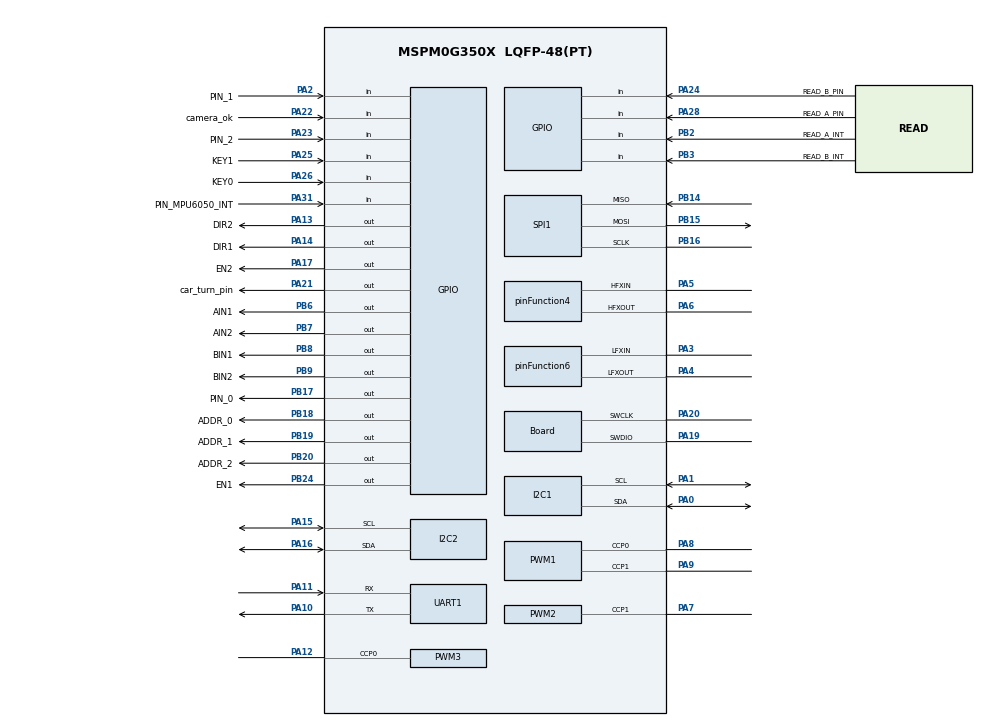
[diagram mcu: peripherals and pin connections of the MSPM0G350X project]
/**
 * @cliArgs --device "MSPM0G350X" --part "Default" --package "LQFP-48(PT)" --product "mspm0_sdk@2.05.01.00"
 * @versions {"tool":"1.24.1+4189"}
 */

/**
 * Import the modules used in this configuration.
 */
const ADC12   = scripting.addModule("/ti/driverlib/ADC12", {}, false);
const ADC121  = ADC12.addInstance();
const Board   = scripting.addModule("/ti/driverlib/Board");
const GPIO    = scripting.addModule("/ti/driverlib/GPIO", {}, false);
const GPIO1   = GPIO.addInstance();
const GPIO2   = GPIO.addInstance();
const GPIO3   = GPIO.addInstance();
const GPIO4   = GPIO.addInstance();
const GPIO5   = GPIO.addInstance();
const GPIO6   = GPIO.addInstance();
const GPIO7   = GPIO.addInstance();
const GPIO8   = GPIO.addInstance();
const GPIO9   = GPIO.addInstance();
const GPIO10  = GPIO.addInstance();
const I2C     = scripting.addModule("/ti/driverlib/I2C", {}, false);
const I2C1    = I2C.addInstance();
const I2C2    = I2C.addInstance();
const PWM     = scripting.addModule("/ti/driverlib/PWM", {}, false);
const PWM1    = PWM.addInstance();
const PWM2    = PWM.addInstance();
const PWM3    = PWM.addInstance();
const SPI     = scripting.addModule("/ti/driverlib/SPI", {}, false);
const SPI1    = SPI.addInstance();
const SYSCTL  = scripting.addModule("/ti/driverlib/SYSCTL");
const SYSTICK = scripting.addModule("/ti/driverlib/SYSTICK");
const TIMER   = scripting.addModule("/ti/driverlib/TIMER", {}, false);
const TIMER1  = TIMER.addInstance();
const TIMER2  = TIMER.addInstance();
const TIMER3  = TIMER.addInstance();
const UART    = scripting.addModule("/ti/driverlib/UART", {}, false);
const UART1   = UART.addInstance();

/**
 * Write custom configuration values to the imported modules.
 */
const divider2       = system.clockTree["HFCLK4MFPCLKDIV"];
divider2.divideValue = 10;

const divider9       = system.clockTree["UDIV"];
divider9.divideValue = 2;

const mux4       = system.clockTree["EXHFMUX"];
mux4.inputSelect = "EXHFMUX_XTAL";

const mux5       = system.clockTree["EXLFMUX"];
mux5.inputSelect = "EXLFMUX_XTAL";

const mux8       = system.clockTree["HSCLKMUX"];
mux8.inputSelect = "HSCLKMUX_SYSPLL2X";

const mux9       = system.clockTree["LFXTMUX"];
mux9.inputSelect = "LFXTMUX_TRUE";

const mux10       = system.clockTree["MFPCLKMUX"];
mux10.inputSelect = "MFPCLKMUX_HFCLK";

const mux12       = system.clockTree["SYSPLLMUX"];
mux12.inputSelect = "zSYSPLLMUX_HFCLK";

const pinFunction4                        = system.clockTree["HFXT"];
pinFunction4.enable                       = true;
pinFunction4.inputFreq                    = 40;
pinFunction4.HFXTStartup                  = 20;
pinFunction4.peripheral.$assign           = "SYSCTL";
pinFunction4.peripheral.hfxInPin.$assign  = "PA5";
pinFunction4.peripheral.hfxOutPin.$assign = "PA6";

const pinFunction6                        = system.clockTree["LFXT"];
pinFunction6.enable                       = true;
pinFunction6.inputFreq                    = 32.768;
pinFunction6.peripheral.$assign           = "SYSCTL";
pinFunction6.peripheral.lfxInPin.$assign  = "PA3";
pinFunction6.peripheral.lfxOutPin.$assign = "PA4";

ADC121.$name                             = "ADC_12_0_GRY";
ADC121.sampClkDiv                        = "DL_ADC12_CLOCK_DIVIDE_8";
ADC121.sampClkSrc                        = "DL_ADC12_CLOCK_ULPCLK";
ADC121.powerDownMode                     = "DL_ADC12_POWER_DOWN_MODE_MANUAL";
ADC121.peripheral.$assign                = "ADC0";
ADC121.peripheral.adcPin0.$assign        = "PA27";
ADC121.adcPin0Config.hideOutputInversion = scripting.forceWrite(false);
ADC121.adcPin0Config.$name               = "ti_driverlib_gpio_GPIOPinGeneric23";

Board.genPeriphPinFile            = true;
Board.peripheral.$assign          = "DEBUGSS";
Board.peripheral.swclkPin.$assign = "PA20";
Board.peripheral.swdioPin.$assign = "PA19";
Board.genFileMod.$name            = "ti_driverlib_BoardPins0";

GPIO1.$name                               = "ENCODER_READ_GRP";
GPIO1.associatedPins.create(4);
GPIO1.associatedPins[0].direction         = "INPUT";
GPIO1.associatedPins[0].$name             = "READ_A_INT";
GPIO1.associatedPins[0].interruptEn       = true;
GPIO1.associatedPins[0].polarity          = "FALL";
GPIO1.associatedPins[0].interruptPriority = "1";
GPIO1.associatedPins[0].pin.$assign       = "PB2";
GPIO1.associatedPins[1].$name             = "READ_B_INT";
GPIO1.associatedPins[1].direction         = "INPUT";
GPIO1.associatedPins[1].interruptEn       = true;
GPIO1.associatedPins[1].polarity          = "FALL";
GPIO1.associatedPins[1].interruptPriority = "1";
GPIO1.associatedPins[1].pin.$assign       = "PB3";
GPIO1.associatedPins[2].assignedPort      = "PORTA";
GPIO1.associatedPins[2].assignedPin       = "28";
GPIO1.associatedPins[2].$name             = "READ_A_PIN";
GPIO1.associatedPins[2].direction         = "INPUT";
GPIO1.associatedPins[2].interruptEn       = true;
GPIO1.associatedPins[2].polarity          = "FALL";
GPIO1.associatedPins[2].interruptPriority = "1";
GPIO1.associatedPins[2].pin.$assign       = "PA28";
GPIO1.associatedPins[3].$name             = "READ_B_PIN";
GPIO1.associatedPins[3].direction         = "INPUT";
GPIO1.associatedPins[3].interruptEn       = true;
GPIO1.associatedPins[3].polarity          = "FALL";
GPIO1.associatedPins[3].interruptPriority = "1";
GPIO1.associatedPins[3].pin.$assign       = "PA24";

GPIO2.$name                         = "TB6612_CONTROL_GRP";
GPIO2.associatedPins.create(4);
GPIO2.associatedPins[0].$name       = "AIN1";
GPIO2.associatedPins[0].pin.$assign = "PB6";
GPIO2.associatedPins[1].$name       = "AIN2";
GPIO2.associatedPins[1].pin.$assign = "PB7";
GPIO2.associatedPins[2].$name       = "BIN1";
GPIO2.associatedPins[2].pin.$assign = "PB8";
GPIO2.associatedPins[3].$name       = "BIN2";
GPIO2.associatedPins[3].pin.$assign = "PB9";

GPIO3.$name                         = "GRY_READ_GRP";
GPIO3.associatedPins.create(3);
GPIO3.associatedPins[0].$name       = "ADDR_0";
GPIO3.associatedPins[0].pin.$assign = "PB18";
GPIO3.associatedPins[1].$name       = "ADDR_1";
GPIO3.associatedPins[1].pin.$assign = "PB19";
GPIO3.associatedPins[2].$name       = "ADDR_2";
GPIO3.associatedPins[2].pin.$assign = "PB20";

GPIO4.$name                               = "GPIO_MPU6050";
GPIO4.associatedPins[0].direction         = "INPUT";
GPIO4.associatedPins[0].$name             = "PIN_MPU6050_INT";
GPIO4.associatedPins[0].interruptEn       = true;
GPIO4.associatedPins[0].polarity          = "FALL";
GPIO4.associatedPins[0].interruptPriority = "1";
GPIO4.associatedPins[0].pin.$assign       = "PA31";

GPIO5.$name                         = "KEYS";
GPIO5.associatedPins.create(2);
GPIO5.associatedPins[0].$name       = "KEY0";
GPIO5.associatedPins[0].direction   = "INPUT";
GPIO5.associatedPins[0].pin.$assign = "PA26";
GPIO5.associatedPins[1].$name       = "KEY1";
GPIO5.associatedPins[1].direction   = "INPUT";
GPIO5.associatedPins[1].pin.$assign = "PA25";

GPIO6.$name                         = "W25Q32_CS";
GPIO6.associatedPins[0].$name       = "PIN_0";
GPIO6.associatedPins[0].pin.$assign = "PB17";

GPIO7.$name                              = "EC11_READ";
GPIO7.associatedPins.create(2);
GPIO7.associatedPins[0].$name            = "PIN_1";
GPIO7.associatedPins[0].direction        = "INPUT";
GPIO7.associatedPins[0].ioStructure      = "SD";
GPIO7.associatedPins[0].internalResistor = "PULL_UP";
GPIO7.associatedPins[0].pin.$assign      = "PA2";
GPIO7.associatedPins[1].$name            = "PIN_2";
GPIO7.associatedPins[1].internalResistor = "PULL_UP";
GPIO7.associatedPins[1].direction        = "INPUT";
GPIO7.associatedPins[1].polarity         = "FALL";
GPIO7.associatedPins[1].interruptEn      = true;
GPIO7.associatedPins[1].ioStructure      = "SD";
GPIO7.associatedPins[1].pin.$assign      = "PA23";

GPIO8.$name                         = "STEP_MOTOR";
GPIO8.associatedPins.create(4);
GPIO8.associatedPins[0].$name       = "EN1";
GPIO8.associatedPins[0].pin.$assign = "PB24";
GPIO8.associatedPins[1].$name       = "EN2";
GPIO8.associatedPins[1].pin.$assign = "PA17";
GPIO8.associatedPins[2].$name       = "DIR1";
GPIO8.associatedPins[2].pin.$assign = "PA14";
GPIO8.associatedPins[3].$name       = "DIR2";
GPIO8.associatedPins[3].pin.$assign = "PA13";

GPIO9.$name                         = "car";
GPIO9.associatedPins[0].$name       = "car_turn_pin";
GPIO9.associatedPins[0].pin.$assign = "PA21";

GPIO10.$name                               = "camera";
GPIO10.associatedPins[0].$name             = "camera_ok";
GPIO10.associatedPins[0].direction         = "INPUT";
GPIO10.associatedPins[0].internalResistor  = "PULL_DOWN";
GPIO10.associatedPins[0].interruptEn       = true;
GPIO10.associatedPins[0].polarity          = "RISE";
GPIO10.associatedPins[0].interruptPriority = "1";
GPIO10.associatedPins[0].pin.$assign       = "PA22";

I2C1.basicEnableController             = true;
I2C1.basicControllerStandardBusSpeed   = "Fast";
I2C1.$name                             = "I2C_MPU6050";
I2C1.peripheral.$assign                = "I2C0";
I2C1.peripheral.sdaPin.$assign         = "PA0";
I2C1.peripheral.sclPin.$assign         = "PA1";
I2C1.sdaPinConfig.hideOutputInversion  = scripting.forceWrite(false);
I2C1.sdaPinConfig.onlyInternalResistor = scripting.forceWrite(false);
I2C1.sdaPinConfig.passedPeripheralType = scripting.forceWrite("Digital");
I2C1.sdaPinConfig.$name                = "ti_driverlib_gpio_GPIOPinGeneric13";
I2C1.sclPinConfig.hideOutputInversion  = scripting.forceWrite(false);
I2C1.sclPinConfig.onlyInternalResistor = scripting.forceWrite(false);
I2C1.sclPinConfig.passedPeripheralType = scripting.forceWrite("Digital");
I2C1.sclPinConfig.$name                = "ti_driverlib_gpio_GPIOPinGeneric14";

I2C2.$name                             = "I2C_1_OLED";
I2C2.basicEnableController             = true;
I2C2.basicControllerStandardBusSpeed   = "Fast";
I2C2.enableDMAEvent2                   = false;
I2C2.peripheral.$assign                = "I2C1";
I2C2.peripheral.sdaPin.$assign         = "PA16";
I2C2.peripheral.sclPin.$assign         = "PA15";
I2C2.sdaPinConfig.hideOutputInversion  = scripting.forceWrite(false);
I2C2.sdaPinConfig.onlyInternalResistor = scripting.forceWrite(false);
I2C2.sdaPinConfig.passedPeripheralType = scripting.forceWrite("Digital");
I2C2.sdaPinConfig.$name                = "ti_driverlib_gpio_GPIOPinGeneric11";
I2C2.sclPinConfig.hideOutputInversion  = scripting.forceWrite(false);
I2C2.sclPinConfig.onlyInternalResistor = scripting.forceWrite(false);
I2C2.sclPinConfig.passedPeripheralType = scripting.forceWrite("Digital");
I2C2.sclPinConfig.$name                = "ti_driverlib_gpio_GPIOPinGeneric12";

PWM1.$name                      = "PWM_0";
PWM1.clockDivider               = 4;
PWM1.pwmMode                    = "EDGE_ALIGN_UP";
PWM1.clockPrescale              = 10;
PWM1.peripheral.$assign         = "TIMA0";
PWM1.peripheral.ccp0Pin.$assign = "PA8";
PWM1.peripheral.ccp1Pin.$assign = "PA9";
PWM1.PWM_CHANNEL_0.$name        = "ti_driverlib_pwm_PWMTimerCC0";
PWM1.PWM_CHANNEL_1.$name        = "ti_driverlib_pwm_PWMTimerCC1";
PWM1.ccp0PinConfig.$name        = "ti_driverlib_gpio_GPIOPinGeneric18";
PWM1.ccp1PinConfig.$name        = "ti_driverlib_gpio_GPIOPinGeneric17";

PWM2.ccIndex                            = [1];
PWM2.$name                              = "PWM_C";
PWM2.clockDivider                       = 8;
PWM2.pwmMode                            = "CENTER_ALIGN";
PWM2.clockPrescale                      = 100;
PWM2.interrupts                         = ["CC1_UP_EVENT"];
PWM2.interruptPriority                  = "0";
PWM2.ccp1PinConfig.$name                = "ti_driverlib_gpio_GPIOPinGeneric8";
PWM2.ccp1PinConfig.direction            = scripting.forceWrite("OUTPUT");
PWM2.ccp1PinConfig.hideOutputInversion  = scripting.forceWrite(false);
PWM2.ccp1PinConfig.onlyInternalResistor = scripting.forceWrite(false);
PWM2.ccp1PinConfig.passedPeripheralType = scripting.forceWrite("Digital");
PWM2.peripheral.ccp1Pin.$assign         = "PA7";
PWM2.PWM_CHANNEL_1.$name                = "ti_driverlib_pwm_PWMTimerCC2";

PWM3.ccIndex                            = [0];
PWM3.$name                              = "PWM_D";
PWM3.clockDivider                       = 4;
PWM3.pwmMode                            = "CENTER_ALIGN";
PWM3.clockPrescale                      = 100;
PWM3.interrupts                         = ["CC0_UP_EVENT"];
PWM3.interruptPriority                  = "0";
PWM3.PWM_CHANNEL_0.$name                = "ti_driverlib_pwm_PWMTimerCC3";
PWM3.ccp0PinConfig.$name                = "ti_driverlib_gpio_GPIOPinGeneric9";
PWM3.ccp0PinConfig.direction            = scripting.forceWrite("OUTPUT");
PWM3.ccp0PinConfig.hideOutputInversion  = scripting.forceWrite(false);
PWM3.ccp0PinConfig.onlyInternalResistor = scripting.forceWrite(false);
PWM3.ccp0PinConfig.passedPeripheralType = scripting.forceWrite("Digital");
PWM3.peripheral.ccp0Pin.$assign         = "PA12";

SPI1.$name                      = "SPI_0";
SPI1.frameFormat                = "MOTO3";
SPI1.sclkPinConfig.$name        = "ti_driverlib_gpio_GPIOPinGeneric10";
SPI1.mosiPinConfig.$name        = "ti_driverlib_gpio_GPIOPinGeneric21";
SPI1.misoPinConfig.$name        = "ti_driverlib_gpio_GPIOPinGeneric22";
SPI1.peripheral.$assign         = "SPI1";
SPI1.peripheral.sclkPin.$assign = "PB16";
SPI1.peripheral.mosiPin.$assign = "PB15";
SPI1.peripheral.misoPin.$assign = "PB14";

SYSCTL.forceDefaultClkConfig = true;
SYSCTL.clockTreeEn           = true;
SYSCTL.MFPCLKSource          = "HFCLK";
scripting.suppress("For best practices when the CPUCLK is running at 32MHz and above, clear the flash status bit using DL_FlashCTL_executeClearStatus\\(\\) before executing any flash operation\\. Otherwise there may be false positives\\.", SYSCTL);

SYSTICK.periodEnable      = true;
SYSTICK.interruptEnable   = true;
SYSTICK.systickEnable     = true;
SYSTICK.interruptPriority = "0";
SYSTICK.period            = 16777216;

TIMER1.$name             = "TIMER_0";
TIMER1.timerMode         = "PERIODIC";
TIMER1.timerClkPrescale  = 200;
TIMER1.interrupts        = ["ZERO"];
TIMER1.timerPeriod       = "15ms";
TIMER1.interruptPriority = "2";

TIMER2.$name             = "TIMER_1";
TIMER2.timerMode         = "PERIODIC";
TIMER2.timerPeriod       = "10ms";
TIMER2.timerClkPrescale  = 200;
TIMER2.interrupts        = ["ZERO"];
TIMER2.interruptPriority = "3";

TIMER3.$name             = "TIMER_2";
TIMER3.timerClkDiv       = 8;
TIMER3.timerClkPrescale  = 100;
TIMER3.timerPeriod       = "5ms";
TIMER3.interrupts        = ["ZERO"];
TIMER3.timerMode         = "PERIODIC";
TIMER3.interruptPriority = "3";

UART1.$name                    = "UART_0";
UART1.targetBaudRate           = 115200;
UART1.enabledInterrupts        = ["RX"];
UART1.interruptPriority        = "1";
UART1.peripheral.$assign       = "UART0";
UART1.peripheral.rxPin.$assign = "PA11";
UART1.peripheral.txPin.$assign = "PA10";
UART1.txPinConfig.$name        = "ti_driverlib_gpio_GPIOPinGeneric6";
UART1.rxPinConfig.$name        = "ti_driverlib_gpio_GPIOPinGeneric7";

const ProjectConfig              = scripting.addModule("/ti/project_config/ProjectConfig", {}, false);
ProjectConfig.migrationCondition = true;

/**
 * Pinmux solution for unlocked pins/peripherals. This ensures that minor changes to the automatic solver in a future
 * version of the tool will not impact the pinmux you originally saw.  These lines can be completely deleted in order to
 * re-solve from scratch.
 */
PWM2.peripheral.$suggestSolution   = "TIMG7";
PWM3.peripheral.$suggestSolution   = "TIMG0";
TIMER1.peripheral.$suggestSolution = "TIMG8";
TIMER2.peripheral.$suggestSolution = "TIMG6";
TIMER3.peripheral.$suggestSolution = "TIMA1";
